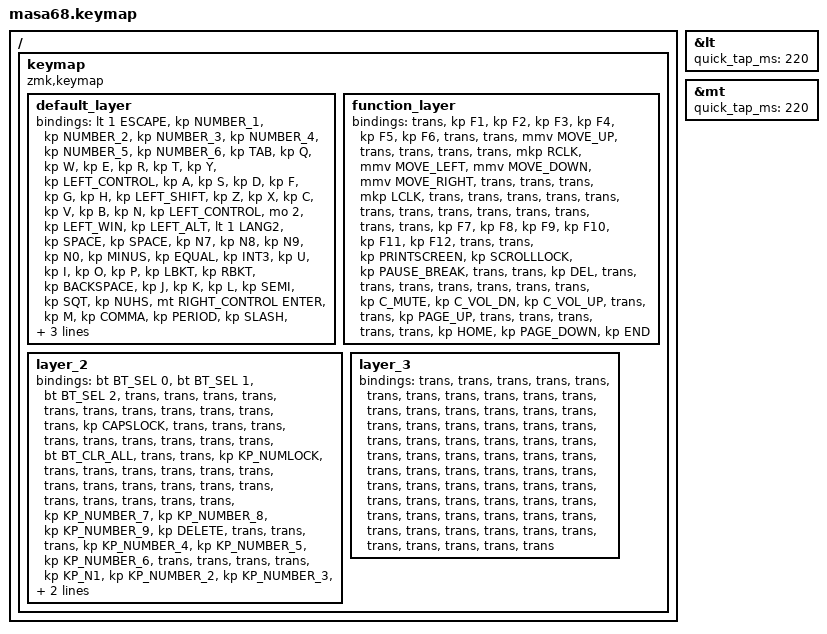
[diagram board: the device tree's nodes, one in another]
/*
 * Copyright (c) 2020 The ZMK Contributors
 *
 * SPDX-License-Identifier: MIT
 */

#include <behaviors.dtsi>
#include <dt-bindings/zmk/bt.h>
#include <dt-bindings/zmk/keys.h>
#include <dt-bindings/zmk/pointing.h>

#define ZMK_POINTING_DEFAULT_MOVE_VAL 1500  // default: 600
#define ZMK_POINTING_DEFAULT_SCRL_VAL 20    // default: 10
#define DEF 0
#define FUN 1

&lt { quick_tap_ms = <220>; };

&mt { quick_tap_ms = <220>; };

/ {
    keymap {
        compatible = "zmk,keymap";

        default_layer {
            bindings = <
&lt 1 ESCAPE  &kp NUMBER_1  &kp NUMBER_2  &kp NUMBER_3  &kp NUMBER_4  &kp NUMBER_5  &kp NUMBER_6  &kp TAB  &kp Q  &kp W  &kp E  &kp R  &kp T  &kp Y  &kp LEFT_CONTROL  &kp A  &kp S  &kp D  &kp F  &kp G  &kp H  &kp LEFT_SHIFT  &kp Z  &kp X  &kp C  &kp V  &kp B  &kp N  &kp LEFT_CONTROL  &mo 2  &kp LEFT_WIN  &kp LEFT_ALT  &lt 1 LANG2  &kp SPACE  &kp SPACE  &kp N7  &kp N8  &kp N9  &kp N0  &kp MINUS  &kp EQUAL  &kp INT3  &kp U  &kp I  &kp O  &kp P  &kp LBKT  &kp RBKT  &kp BACKSPACE  &kp J  &kp K  &kp L  &kp SEMI  &kp SQT  &kp NUHS  &mt RIGHT_CONTROL ENTER  &kp M  &kp COMMA  &kp PERIOD  &kp SLASH  &kp INT1  &kp UP  &mo 2  &kp LANG1  &kp RIGHT_ALT  &kp RIGHT_ALT  &mo 1  &kp LEFT  &kp DOWN  &kp RIGHT
            >;
        };

        function_layer {
            bindings = <
&trans  &kp F1  &kp F2  &kp F3  &kp F4  &kp F5  &kp F6  &trans  &trans  &mmv MOVE_UP  &trans  &trans  &trans  &trans  &mkp RCLK  &mmv MOVE_LEFT  &mmv MOVE_DOWN  &mmv MOVE_RIGHT  &trans  &trans  &trans  &mkp LCLK  &trans  &trans  &trans  &trans  &trans  &trans  &trans  &trans  &trans  &trans  &trans  &trans  &trans  &kp F7  &kp F8  &kp F9  &kp F10  &kp F11  &kp F12  &trans  &trans  &kp PRINTSCREEN  &kp SCROLLLOCK  &kp PAUSE_BREAK  &trans  &trans  &kp DEL  &trans  &trans  &trans  &trans  &trans  &trans  &trans  &kp C_MUTE  &kp C_VOL_DN  &kp C_VOL_UP  &trans  &trans  &kp PAGE_UP  &trans  &trans  &trans  &trans  &trans  &kp HOME  &kp PAGE_DOWN  &kp END
            >;
        };

        layer_2 {
            bindings = <
&bt BT_SEL 0  &bt BT_SEL 1  &bt BT_SEL 2  &trans  &trans  &trans  &trans  &trans  &trans  &trans  &trans  &trans  &trans  &trans  &kp CAPSLOCK  &trans  &trans  &trans  &trans  &trans  &trans  &trans  &trans  &trans  &bt BT_CLR_ALL  &trans  &trans  &kp KP_NUMLOCK  &trans  &trans  &trans  &trans  &trans  &trans  &trans  &trans  &trans  &trans  &trans  &trans  &trans  &trans  &trans  &trans  &trans  &kp KP_NUMBER_7  &kp KP_NUMBER_8  &kp KP_NUMBER_9  &kp DELETE  &trans  &trans  &trans  &kp KP_NUMBER_4  &kp KP_NUMBER_5  &kp KP_NUMBER_6  &trans  &trans  &trans  &trans  &kp KP_N1  &kp KP_NUMBER_2  &kp KP_NUMBER_3  &trans  &trans  &trans  &trans  &kp KP_NUMBER_0  &kp KP_DOT  &trans  &trans
            >;
        };

        layer_3 {
            bindings = <
&trans  &trans  &trans  &trans  &trans  &trans  &trans  &trans  &trans  &trans  &trans  &trans  &trans  &trans  &trans  &trans  &trans  &trans  &trans  &trans  &trans  &trans  &trans  &trans  &trans  &trans  &trans  &trans  &trans  &trans  &trans  &trans  &trans  &trans  &trans  &trans  &trans  &trans  &trans  &trans  &trans  &trans  &trans  &trans  &trans  &trans  &trans  &trans  &trans  &trans  &trans  &trans  &trans  &trans  &trans  &trans  &trans  &trans  &trans  &trans  &trans  &trans  &trans  &trans  &trans  &trans  &trans  &trans  &trans  &trans
            >;
        };
    };
};
